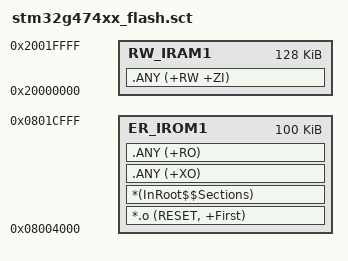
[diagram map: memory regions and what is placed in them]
LR_IROM1 0x8004000 0x00019000  {  ; App region = 100 KB. 16 KB bootloader below; above the App sit 10 KB calibration tables (5 pages @0x0801D000) then the 2 KB config-log page, both kept out of the App image
  ER_IROM1 0x8004000 0x00019000  {  ; load address = excetion address
   *.o (RESET, +First)
   *(InRoot$$Sections)
   .ANY (+XO)
   .ANY (+RO)
  }
  RW_IRAM1 0x20000000 0x00020000  {  ; load address = excetion address
   .ANY (+RW +ZI)
  }
;***region***;
;***endregion***;
}


/*-Start of  regions- Auto-generated By STM32CubeMX-*/
